# spixr_reva_me10 register map
Registers are read-write, no defined reset value unless marked. A register's access mark holds for its fields unless they carry their own. Offsets are from the block's base; lines under a group give offsets from that group; [hi:lo] are bit positions; {n}, {i} and the like mark numbered series; 'fields as' and 'values as' point back to an identical list; <NAME> marks a mode.

## Memory map
0x4003A000 SPIXR size 0x1000 — SPIXR peripheral.

## SPIXR — SPIXR peripheral.
Base 0x4003A000
0x00 DATA32 32-bit — Register for reading and writing the FIFO.
  [31:0] DATA — Read to pull from RX FIFO, write to put into TX FIFO.
{0x0+2i} DATA16[{i}] (i=0..1) 16-bit (alternate view of DATA32) — Register for reading and writing the FIFO.
  [15:0] DATA — Read to pull from RX FIFO, write to put into TX FIFO.
{0x0+i} DATA8[{i}] (i=0..3) 8-bit (alternate view of DATA32) — Register for reading and writing the FIFO.
  [7:0] DATA — Read to pull from RX FIFO, write to put into TX FIFO.
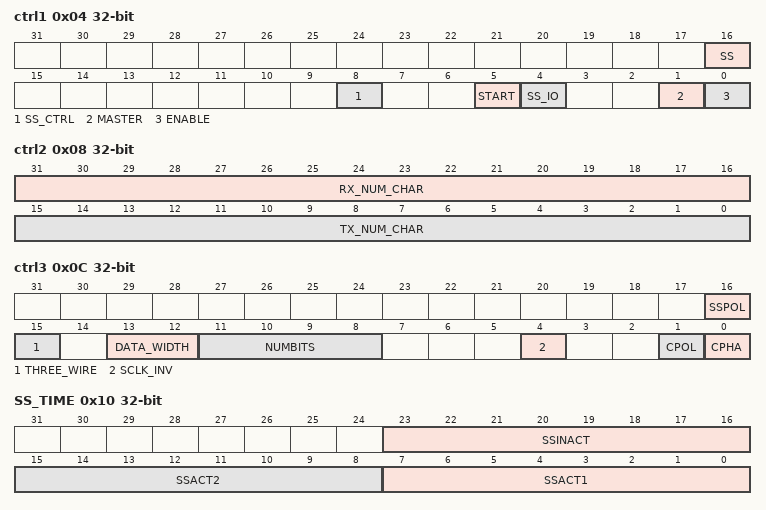
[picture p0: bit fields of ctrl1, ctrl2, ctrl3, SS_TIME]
0x04 ctrl1 — Register for controlling SPI peripheral.
  [16] SS — Slave Select, when in Master mode selects which Slave devices are selected. More than one Slave device can be selected.
  [8] SS_CTRL — Slave Select Control.
    0=deassert (SPI de-asserts Slave Select at the end of a transaction.); 1=assert (SPI leaves Slave Select asserted at the end of a transaction.)
  [5] START — Start Transmit.
    1=start (Master Initiates a transaction, this bit is self clearing when transactions are done. If a transaction completes, and the TX FIFO is empty, the Master halts, if a transaction completes, and the TX FIFO is not empty, the Master initiates another transaction.)
  [4] SS_IO — Slave Select 0, IO direction, to support Multi-Master mode, Slave Select 0 can be input in Master mode. This bit has no effect in slave mode.
    0=output (Slave select 0 is output.); 1=input (Slave Select 0 is input, only valid if MMEN=1.)
  [1] MASTER — Master Mode Enable.
    0=dis (SPI is Slave mode.); 1=en (SPI is Master mode.)
  [0] ENABLE — SPI Enable.
    0=dis (SPI is disabled.); 1=en (SPI is enabled.)
0x08 ctrl2 — Register for controlling SPI peripheral.
  [31:16] RX_NUM_CHAR — Nubmer of Characters to receive.
  [15:0] TX_NUM_CHAR — Nubmer of Characters to transmit.
0x0C ctrl3 — Register for controlling SPI peripheral.
  [16] SSPOL — Slave Select Polarity
    0=activeLow (Slave select is active low.); 1=activeHigh (Slave select is active high.)
  [15] THREE_WIRE — Three Wire mode. MOSI/MISO pin (s) shared. Only Mono mode suports Four-Wire.
    0=4wire (Use four wire mode (Mono only).); 1=3wire (Use three wire mode.)
  [13:12] DATA_WIDTH — SPI Data width.
    0=Mono (1 data pin.); 1=Dual (2 data pins.); 2=Quad (4 data pins.)
  [11:8] NUMBITS — Number of Bits per character.
    0=16BITS (16 bits per character.); {v}={v}BITS ({v} bits per character.) (v=1..15)
  [4] SCLK_INV — Invert SCLK Feedback in Master Mode.
    0=Normal (SCLK is not inverted to Line Receiver.)
  [1] CPOL — Clock Polarity.
    0=Normal clock; 1=Inverted clock
  [0] CPHA — Clock Phase.
    0=risingEdge (Data sampled on rising edge.); 1=fallingEdge (Data sample on falling edge.)
0x10 SS_TIME — Register for controlling SPI peripheral.
  [23:16] SSINACT — Slave Select Inactive delay.
  [15:8] SSACT2 — Slave Select Action delay 2.
  [7:0] SSACT1 — Slave Select Action delay 1.
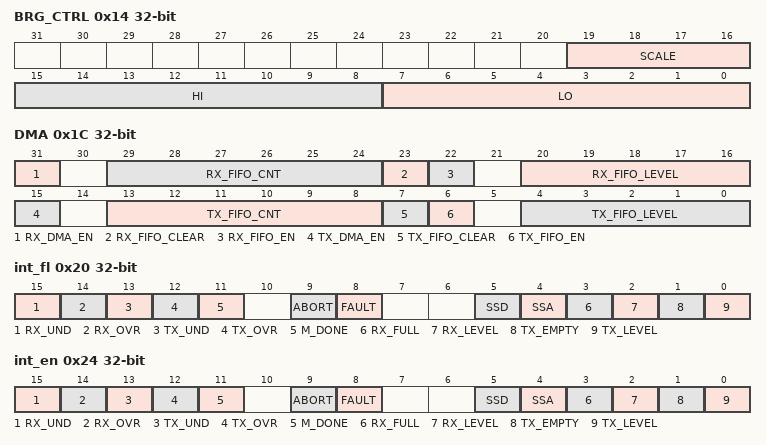
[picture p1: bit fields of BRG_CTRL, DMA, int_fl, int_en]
0x14 BRG_CTRL — Register for controlling SPI clock rate.
  [19:16] SCALE — System Clock scale factor. Scales the AMBA clock by 2^SCALE before generating serial clock.
    0=div1 (clk_freq = f_pclk/1.); 1=div2 (clk_freq = f_pclk/2.); 2=div4 (clk_freq = f_pclk/4.); 3=div8 (clk_freq = f_pclk/8.); 4=div16 (clk_freq = f_pclk/16.); 5=div32 (clk_freq = f_pclk/32.); 6=div64 (clk_freq = f_pclk/64.); 7=div128 (clk_freq = f_pclk/128.); 8=div256 (clk_freq = f_pclk/256.)
  [15:8] HI — High duty cycle control. In timer mode, reload[15:8].
  [7:0] LO — Low duty cycle control. In timer mode, reload[7:0].
0x1C DMA — Register for controlling DMA.
  [31] RX_DMA_EN — RX DMA Enable.
    0=dis (RX DMA requests are disabled, any pending DMA requests are cleared.); 1=en (RX DMA requests are enabled.)
  [29:24] RX_FIFO_CNT — Count of entries in RX FIFO.
  [23] RX_FIFO_CLEAR — Clear RX FIFO, clear is accomplished by resetting the read and write pointers. This should be done when FIFO is not being accessed on the SPI side.
    1=Clear the Receive FIFIO, clears any pending RX FIFO status
  [22] RX_FIFO_EN — Receive FIFO enabled for SPI transactions.
    0=dis (Receive FIFO is not enabled.); 1=en (Receive FIFO is enabled.)
  [20:16] RX_FIFO_LEVEL — Receive FIFO level that will trigger a DMA request, also level for threshold status. When RX FIFO has more than this many bytes, the associated events and conditions are triggered.
  [15] TX_DMA_EN — TX DMA Enable.
    0=dis (TX DMA requests are disabled, andy pending DMA requests are cleared.); 1=en (TX DMA requests are enabled.)
  [13:8] TX_FIFO_CNT — Count of entries in TX FIFO.
  [7] TX_FIFO_CLEAR — Clear TX FIFO, clear is accomplished by resetting the read and write pointers. This should be done when FIFO is not being accessed on the SPI side.
    1=Clear the Transmit FIFO, clears any pending TX FIFO status
  [6] TX_FIFO_EN — Transmit FIFO enabled for SPI transactions.
    0=dis (Transmit FIFO is not enabled.); 1=en (Transmit FIFO is enabled.)
  [4:0] TX_FIFO_LEVEL — Transmit FIFO level that will trigger a DMA request, also level for threshold status. When TX FIFO has fewer than this many bytes, the associated events and conditions are triggered.
0x20 int_fl — Register for reading and clearing interrupt flags. All bits are write 1 to clear.
  [all] fields
    1=clear (Flag is set when value read is 1. Write 1 to clear this flag.)
  [15] RX_UND — Receive FIFO Underrun, set when the AMBA side attempts to read data from an empty receive FIFO.
  [14] RX_OVR — Receive FIFO Overrun, set when the SPI side attempts to write to a full receive FIFO.
  [13] TX_UND — Transmit FIFO Underrun, set when the SPI side attempts to read data from an empty transmit FIFO.
  [12] TX_OVR — Transmit FIFO Overrun, set when the AMBA side attempts to write data to a full transmit FIFO.
  [11] M_DONE — Master Done, set when SPI Master has completed any transactions.
  [9] ABORT — Slave Abort Detected.
  [8] FAULT — Multi-Master Mode Fault.
  [5] SSD — Slave Select Deasserted.
  [4] SSA — Slave Select Asserted.
  [3] RX_FULL — RX FIFO FULL.
  [2] RX_LEVEL — RX FIFO Threshold Crossed.
  [1] TX_EMPTY — TX FIFO Empty.
  [0] TX_LEVEL — TX FIFO Threshold Crossed.
0x24 int_en — Register for enabling interrupts.
  [all] fields
    0=dis (Interrupt is disabled.); 1=en (Interrupt is enabled.)
  [15] RX_UND — Receive FIFO Underrun interrupt enable.
  [14] RX_OVR — Receive FIFO Overrun interrupt enable.
  [13] TX_UND — Transmit FIFO Underrun interrupt enable.
  [12] TX_OVR — Transmit FIFO Overrun interrupt enable.
  [11] M_DONE — Master Done interrupt enable.
  [9] ABORT — Slave Abort Detected interrupt enable.
  [8] FAULT — Multi-Master Mode Fault interrupt enable.
  [5] SSD — Slave Select Deasserted interrupt enable.
  [4] SSA — Slave Select Asserted interrupt enable.
  [3] RX_FULL — RX FIFO FULL interrupt enable.
  [2] RX_LEVEL — RX FIFO Threshold Crossed interrupt enable.
  [1] TX_EMPTY — TX FIFO Empty interrupt enable.
  [0] TX_LEVEL — TX FIFO Threshold interrupt enable.
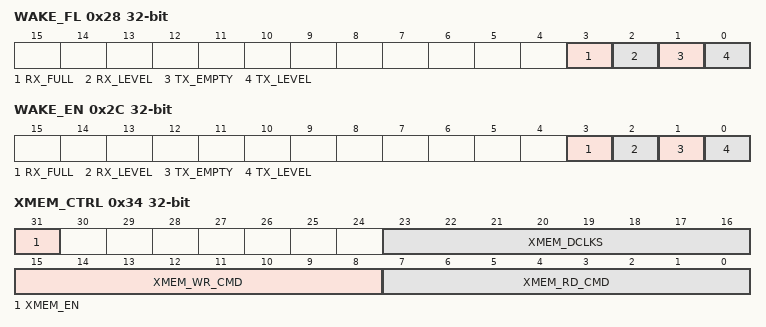
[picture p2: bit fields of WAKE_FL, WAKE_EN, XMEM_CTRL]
0x28 WAKE_FL — Register for wake up flags. All bits in this register are write 1 to clear.
  [all] fields
    values as the fields of int_fl
  [3] RX_FULL — Wake on RX FIFO Full.
  [2] RX_LEVEL — Wake on RX FIFO Threshold Crossed.
  [1] TX_EMPTY — Wake on TX FIFO Empty.
  [0] TX_LEVEL — Wake on TX FIFO Threshold Crossed.
0x2C WAKE_EN — Register for wake up enable.
  [all] fields
    0=dis (Wakeup source disabled.); 1=en (Wakeup source enabled.)
  [3] RX_FULL — Wake on RX FIFO Full Enable.
  [2] RX_LEVEL — Wake on RX FIFO Threshold Crossed Enable.
  [1] TX_EMPTY — Wake on TX FIFO Empty Enable.
  [0] TX_LEVEL — Wake on TX FIFO Threshold Crossed Enable.
0x30 STAT ro — SPI Status register.
  [0] BUSY — SPI active status. In Master mode, set when transaction starts, cleared when last bit of last character is acted upon and Slave Select de-assertion would occur. In Slave mode, set when Slave Select is asserted, cleared when Slave Select is de-asserted. Not used in Timer mode.
    0=notActive (SPI not active.); 1=active (SPI active.)
0x34 XMEM_CTRL — Register to control external memory.
  [31] XMEM_EN — XMEM enable.
    0=dis (External memory disabled.); 1=en (External memory enabled.)
  [23:16] XMEM_DCLKS — Dummy clocks.
  [15:8] XMEM_WR_CMD — Write command.
  [7:0] XMEM_RD_CMD — Read command.
